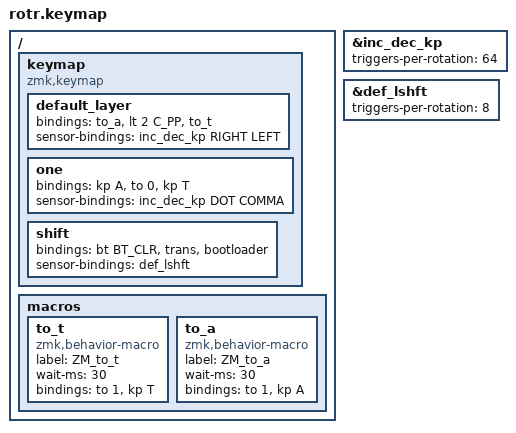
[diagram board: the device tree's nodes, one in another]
#include <behaviors.dtsi>
#include <dt-bindings/zmk/bt.h>
#include <dt-bindings/zmk/rgb.h>
#include <dt-bindings/zmk/keys.h>

&inc_dec_kp {
    triggers-per-rotation = <64>;
};
&def_lshft {
    triggers-per-rotation = <8>;
};

/ {
    keymap {
        compatible = "zmk,keymap";
        default_layer {
            bindings = <&to_a &lt 2 C_PP &to_t>;
            sensor-bindings = <&inc_dec_kp RIGHT LEFT>;
        };
        one {
            bindings = <&kp A &to 0 &kp T>;
            sensor-bindings = <&inc_dec_kp DOT COMMA>;
        };
        shift {
            bindings = <&bt BT_CLR &trans &bootloader>;
            sensor-bindings = <&def_lshft>;
        };
    };

    /*behaviors {
        // optional second incrementer that
        // provides a different resolution
        inc_dec_precise: behavior_sensor_rotate_key_press_2 {
            compatible = "zmk,behavior-sensor-rotate-key-press";
            label = "ENC_KEY_PRESS_2";
            triggers-per-rotation = <256>;
            #sensor-binding-cells = <2>;
        };
    };*/

    macros {
        to_t: to_t {
            label = "ZM_to_t";
            compatible = "zmk,behavior-macro";
            #binding-cells = <0>;
            wait-ms = <30>;
            bindings = <&to 1>, <&kp T>;
        };
        to_a: to_a {
            label = "ZM_to_a";
            compatible = "zmk,behavior-macro";
            #binding-cells = <0>;
            wait-ms = <30>;
            bindings = <&to 1>, <&kp A>;
        };
    };
};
